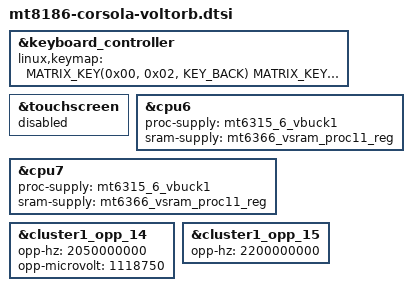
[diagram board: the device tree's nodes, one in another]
// SPDX-License-Identifier: (GPL-2.0 OR MIT)
/*
 * Copyright 2022 Google LLC
 */

/dts-v1/;
#include "mt8186-corsola-steelix.dtsi"
#include "mt6315.dtsi"

/ {
	/delete-node/ gpio-keys;
};

&keyboard_controller {
	linux,keymap = <
		MATRIX_KEY(0x00, 0x02, KEY_BACK)
		MATRIX_KEY(0x03, 0x02, KEY_REFRESH)
		MATRIX_KEY(0x02, 0x02, KEY_ZOOM)
		MATRIX_KEY(0x01, 0x02, KEY_SCALE)
		MATRIX_KEY(0x03, 0x04, KEY_SYSRQ)
		MATRIX_KEY(0x02, 0x04, KEY_BRIGHTNESSDOWN)
		MATRIX_KEY(0x01, 0x04, KEY_BRIGHTNESSUP)
		MATRIX_KEY(0x02, 0x09, KEY_MUTE)
		MATRIX_KEY(0x01, 0x09, KEY_VOLUMEDOWN)
		MATRIX_KEY(0x00, 0x04, KEY_VOLUMEUP)
		CROS_STD_MAIN_KEYMAP
	>;
};

&touchscreen {
	status = "disabled";
};

&cpu6 {
	proc-supply = <&mt6315_6_vbuck1>;
	sram-supply = <&mt6366_vsram_proc11_reg>;
};

&cpu7 {
	proc-supply = <&mt6315_6_vbuck1>;
	sram-supply = <&mt6366_vsram_proc11_reg>;
};

&cluster1_opp_14 {
	opp-hz = /bits/ 64 <2050000000>;
	opp-microvolt = <1118750>;
};

&cluster1_opp_15 {
	opp-hz = /bits/ 64 <2200000000>;
};
